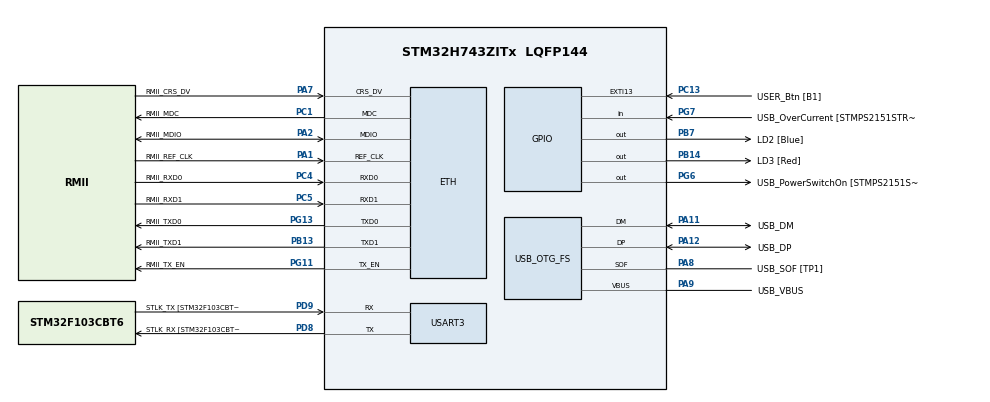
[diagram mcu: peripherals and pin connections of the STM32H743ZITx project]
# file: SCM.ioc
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CORTEX_M7.CPU_DCache=Enabled
CORTEX_M7.CPU_ICache=Disabled
ETH.MACAddr=00\:80\:E1\:00\:20\:10
ETH.MediaInterface=HAL_ETH_RMII_MODE
FREERTOS.Tasks01=defaultTask,0,128,StartDefaultTask,Default,NULL,Dynamic,NULL,NULL
FREERTOS.configENABLE_FPU=1
FREERTOS.configTOTAL_HEAP_SIZE=32768
FREERTOS.configUSE_NEWLIB_REENTRANT=1
Mcu.Family=STM32H7
Mcu.Name=STM32H743ZITx
Mcu.Package=LQFP144
NVIC.HASH_RNG_IRQn=true\:5\:0\:false\:false\:true\:true\:true\:true
NVIC.PriorityGroup=NVIC_PRIORITYGROUP_4
NVIC.TIM1_UP_IRQn=true\:15\:0\:false\:false\:true\:false\:false\:true
NVIC.TimeBase=TIM1_UP_IRQn
NVIC.TimeBaseIP=TIM1
PA1.GPIO_Label=RMII_REF_CLK
PA1.Mode=RMII
PA1.Signal=ETH_REF_CLK
PA10.GPIO_Label=USB_ID
PA10.Signal=USB_OTG_FS_ID
PA11.GPIO_Label=USB_DM
PA11.Mode=Device_Only
PA11.Signal=USB_OTG_FS_DM
PA12.GPIO_Label=USB_DP
PA12.Mode=Device_Only
PA12.Signal=USB_OTG_FS_DP
PA2.GPIO_Label=RMII_MDIO
PA2.Mode=RMII
PA2.Signal=ETH_MDIO
PA7.GPIO_Label=RMII_CRS_DV
PA7.Mode=RMII
PA7.Signal=ETH_CRS_DV
PA8.GPIO_Label=USB_SOF [TP1]
PA8.Mode=Activate_SOF_FS
PA8.Signal=USB_OTG_FS_SOF
PA9.GPIO_Label=USB_VBUS
PA9.Mode=Activate_VBUS
PA9.Signal=USB_OTG_FS_VBUS
PB13.GPIO_Label=RMII_TXD1
PB13.Mode=RMII
PB13.Signal=ETH_TXD1
PB14.GPIO_Label=LD3 [Red]
PB14.Signal=GPIO_Output
PB7.GPIO_Label=LD2 [Blue]
PB7.Signal=GPIO_Output
PC1.GPIO_Label=RMII_MDC
PC1.Mode=RMII
PC1.Signal=ETH_MDC
PC13.GPIO_Label=USER_Btn [B1]
PC13.Signal=GPXTI13
PC14-OSC32_IN\ (OSC32_IN).Mode=LSE-External-Oscillator
PC14-OSC32_IN\ (OSC32_IN).Signal=RCC_OSC32_IN
PC15-OSC32_OUT\ (OSC32_OUT).Mode=LSE-External-Oscillator
PC15-OSC32_OUT\ (OSC32_OUT).Signal=RCC_OSC32_OUT
PC4.GPIO_Label=RMII_RXD0
PC4.Mode=RMII
PC4.Signal=ETH_RXD0
PC5.GPIO_Label=RMII_RXD1
PC5.Mode=RMII
PC5.Signal=ETH_RXD1
PD8.GPIO_Label=STLK_RX [STM32F103CBT6_PA3]
PD8.Mode=Asynchronous
PD8.Signal=USART3_TX
PD9.GPIO_Label=STLK_TX [STM32F103CBT6_PA2]
PD9.Mode=Asynchronous
PD9.Signal=USART3_RX
PG11.GPIO_Label=RMII_TX_EN
PG11.Mode=RMII
PG11.Signal=ETH_TX_EN
PG13.GPIO_Label=RMII_TXD0
PG13.Mode=RMII
PG13.Signal=ETH_TXD0
PG6.GPIO_Label=USB_PowerSwitchOn [STMPS2151STR_EN]
PG6.Signal=GPIO_Output
PG7.GPIO_Label=USB_OverCurrent [STMPS2151STR_FAULT]
PG7.Signal=GPIO_Input
PH0-OSC_IN\ (PH0).GPIO_Label=MCO
PH0-OSC_IN\ (PH0).Mode=HSE-External-Clock-Source
PH0-OSC_IN\ (PH0).Signal=RCC_OSC_IN
PH1-OSC_OUT\ (PH1).Signal=RCC_OSC_OUT
ProjectManager.HeapSize=0x200
ProjectManager.StackSize=0x400
ProjectManager.TargetToolchain=STM32CubeIDE
RCC.48MHZClocksFreq_Value=24000000
RCC.ADCFreq_Value=16125000
RCC.AHBFreq_Value=216000000
RCC.APB1CLKDivider=RCC_HCLK_DIV4
RCC.APB1Freq_Value=60000000
RCC.APB1TimFreq_Value=108000000
RCC.APB2CLKDivider=RCC_HCLK_DIV2
RCC.APB2Freq_Value=120000000
RCC.APB2TimFreq_Value=216000000
RCC.APB3Freq_Value=120000000
RCC.APB4Freq_Value=120000000
RCC.CortexFreq_Value=240000000
RCC.D1PPRE=RCC_APB3_DIV2
RCC.D2PPRE1=RCC_APB1_DIV4
RCC.D2PPRE2=RCC_APB2_DIV2
RCC.D3PPRE=RCC_APB4_DIV2
RCC.DIVM1=1
RCC.DIVN1=60
RCC.DIVQ1=8
RCC.HCLKFreq_Value=240000000
RCC.HSE_VALUE=8000000
RCC.HSI_VALUE=64000000
RCC.PLLFRACN=0
RCC.PLLM=25
RCC.PLLMUL=RCC_PLL_MUL9
RCC.PLLN=432
RCC.PLLQ=9
RCC.PRESCALERUSB=RCC_USBCLKSOURCE_PLL_DIV1_5
RCC.PWR_Regulator_Voltage_Scale=PWR_REGULATOR_VOLTAGE_SCALE1
RCC.SYSCLKFreq_VALUE=240000000
RCC.SYSCLKSource=RCC_SYSCLKSOURCE_PLLCLK
RCC.SYSCLKSourceVirtual=RCC_SYSCLKSOURCE_PLLCLK
RCC.USBFreq_Value=60000000
RCC.VCOOutputFreq_Value=432000000
USART3.VirtualMode-Asynchronous=VM_ASYNC
USB_OTG_FS.VirtualMode=Device_Only
VP_FREERTOS_VS_CMSIS_V1.Mode=CMSIS_V1
VP_RNG_VS_RNG.Mode=RNG_Activate
VP_SYS_VS_tim1.Mode=TIM1
board=NUCLEO-H743ZI

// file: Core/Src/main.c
/* USER CODE BEGIN Header */
/**
  ******************************************************************************
  * @file           : main.c
  * @brief          : Main program body
  ******************************************************************************
  * @attention
  *
  * <h2><center>&copy; Copyright (c) 2021 STMicroelectronics.
  * All rights reserved.</center></h2>
  *
  * This software component is licensed by ST under BSD 3-Clause license,
  * the "License"; You may not use this file except in compliance with the
  * License. You may obtain a copy of the License at:
  *                        opensource.org/licenses/BSD-3-Clause
  *
  ******************************************************************************
  */
/* USER CODE END Header */
#include "main.h"
#include "string.h"
#include "cmsis_os.h"

/* USER CODE BEGIN Includes */
#include "freertos_functions.h"

/* USER CODE END Includes */

#if defined ( __ICCARM__ ) /*!< IAR Compiler */

#pragma location=0x30040000
ETH_DMADescTypeDef  DMARxDscrTab[ETH_RX_DESC_CNT]; /* Ethernet Rx DMA Descriptors */
#pragma location=0x30040060
ETH_DMADescTypeDef  DMATxDscrTab[ETH_TX_DESC_CNT]; /* Ethernet Tx DMA Descriptors */
#pragma location=0x30040200
uint8_t Rx_Buff[ETH_RX_DESC_CNT][ETH_MAX_PACKET_SIZE]; /* Ethernet Receive Buffers */

#elif defined ( __CC_ARM )  /* MDK ARM Compiler */

__attribute__((at(0x30040000))) ETH_DMADescTypeDef  DMARxDscrTab[ETH_RX_DESC_CNT]; /* Ethernet Rx DMA Descriptors */
__attribute__((at(0x30040060))) ETH_DMADescTypeDef  DMATxDscrTab[ETH_TX_DESC_CNT]; /* Ethernet Tx DMA Descriptors */
__attribute__((at(0x30040200))) uint8_t Rx_Buff[ETH_RX_DESC_CNT][ETH_MAX_PACKET_SIZE]; /* Ethernet Receive Buffer */

#elif defined ( __GNUC__ ) /* GNU Compiler */

ETH_DMADescTypeDef DMARxDscrTab[ETH_RX_DESC_CNT] __attribute__((section(".RxDecripSection"))); /* Ethernet Rx DMA Descriptors */
ETH_DMADescTypeDef DMATxDscrTab[ETH_TX_DESC_CNT] __attribute__((section(".TxDecripSection")));   /* Ethernet Tx DMA Descriptors */
uint8_t Rx_Buff[ETH_RX_DESC_CNT][ETH_MAX_PACKET_SIZE] __attribute__((section(".RxArraySection"))); /* Ethernet Receive Buffers */

#endif

ETH_TxPacketConfig TxConfig;

ETH_HandleTypeDef heth;

RNG_HandleTypeDef hrng;

UART_HandleTypeDef huart3;

PCD_HandleTypeDef hpcd_USB_OTG_FS;

osThreadId defaultTaskHandle;
/* USER CODE BEGIN PV */
osThreadId UnitiSideDataTaskHandle;
/* USER CODE END PV */

void SystemClock_Config(void);
static void MX_GPIO_Init(void);
static void MX_USART3_UART_Init(void);
static void MX_USB_OTG_FS_PCD_Init(void);
static void MX_RNG_Init(void);
static void MX_ETH_Init(void);
void StartDefaultTask(void const * argument);

int main(void)
{

  /* Enable D-Cache---------------------------------------------------------*/
  SCB_EnableDCache();

  /* MCU Configuration--------------------------------------------------------*/

  /* Reset of all peripherals, Initializes the Flash interface and the Systick. */
  HAL_Init();

  /* Configure the system clock */
  SystemClock_Config();

  /* Initialize all configured peripherals */
  MX_GPIO_Init();
  MX_USART3_UART_Init();
  MX_USB_OTG_FS_PCD_Init();
  MX_RNG_Init();
  MX_ETH_Init();

  /* Create the thread(s) */
  /* definition and creation of defaultTask */
  osThreadDef(defaultTask, StartDefaultTask, osPriorityNormal, 0, 128);
  defaultTaskHandle = osThreadCreate(osThread(defaultTask), NULL);

  /* USER CODE BEGIN RTOS_THREADS */
  /* add threads, ... */
  osThreadDef(unit_side_data_task, Unit_Side_Data_Task, osPriorityHigh, 0, 4096);
  UnitiSideDataTaskHandle = osThreadCreate(osThread(unit_side_data_task), NULL);

  osThreadDef(scm_side_data_task, SCM_Side_Data_Task, osPriorityHigh, 0, 4096);
  UnitiSideDataTaskHandle = osThreadCreate(osThread(scm_side_data_task), NULL);
  /* USER CODE END RTOS_THREADS */

  /* Start scheduler */
  osKernelStart();

  /* We should never get here as control is now taken by the scheduler */
  /* Infinite loop */
  while (1)
  {

  }
}

void SystemClock_Config(void)
{
  RCC_OscInitTypeDef RCC_OscInitStruct = {0};
  RCC_ClkInitTypeDef RCC_ClkInitStruct = {0};

  /** Supply configuration update enable
  */
  HAL_PWREx_ConfigSupply(PWR_LDO_SUPPLY);
  /** Configure the main internal regulator output voltage
  */
  __HAL_PWR_VOLTAGESCALING_CONFIG(PWR_REGULATOR_VOLTAGE_SCALE1);

  while(!__HAL_PWR_GET_FLAG(PWR_FLAG_VOSRDY)) {}
  /** Initializes the RCC Oscillators according to the specified parameters
  * in the RCC_OscInitTypeDef structure.
  */
  RCC_OscInitStruct.OscillatorType = RCC_OSCILLATORTYPE_HSI48|RCC_OSCILLATORTYPE_HSE;
  RCC_OscInitStruct.HSEState = RCC_HSE_BYPASS;
  RCC_OscInitStruct.HSI48State = RCC_HSI48_ON;
  RCC_OscInitStruct.PLL.PLLState = RCC_PLL_ON;
  RCC_OscInitStruct.PLL.PLLSource = RCC_PLLSOURCE_HSE;
  RCC_OscInitStruct.PLL.PLLM = 1;
  RCC_OscInitStruct.PLL.PLLN = 60;
  RCC_OscInitStruct.PLL.PLLP = 2;
  RCC_OscInitStruct.PLL.PLLQ = 8;
  RCC_OscInitStruct.PLL.PLLR = 2;
  RCC_OscInitStruct.PLL.PLLRGE = RCC_PLL1VCIRANGE_3;
  RCC_OscInitStruct.PLL.PLLVCOSEL = RCC_PLL1VCOWIDE;
  RCC_OscInitStruct.PLL.PLLFRACN = 0;
  if (HAL_RCC_OscConfig(&RCC_OscInitStruct) != HAL_OK)
  {
    Error_Handler();
  }
  /** Initializes the CPU, AHB and APB buses clocks
  */
  RCC_ClkInitStruct.ClockType = RCC_CLOCKTYPE_HCLK|RCC_CLOCKTYPE_SYSCLK
                              |RCC_CLOCKTYPE_PCLK1|RCC_CLOCKTYPE_PCLK2
                              |RCC_CLOCKTYPE_D3PCLK1|RCC_CLOCKTYPE_D1PCLK1;
  RCC_ClkInitStruct.SYSCLKSource = RCC_SYSCLKSOURCE_PLLCLK;
  RCC_ClkInitStruct.SYSCLKDivider = RCC_SYSCLK_DIV1;
  RCC_ClkInitStruct.AHBCLKDivider = RCC_HCLK_DIV1;
  RCC_ClkInitStruct.APB3CLKDivider = RCC_APB3_DIV2;
  RCC_ClkInitStruct.APB1CLKDivider = RCC_APB1_DIV4;
  RCC_ClkInitStruct.APB2CLKDivider = RCC_APB2_DIV2;
  RCC_ClkInitStruct.APB4CLKDivider = RCC_APB4_DIV2;

  if (HAL_RCC_ClockConfig(&RCC_ClkInitStruct, FLASH_LATENCY_0) != HAL_OK)
  {
    Error_Handler();
  }
}

static void MX_ETH_Init(void)
{

   static uint8_t MACAddr[6];

  heth.Instance = ETH;
  MACAddr[0] = 0x00;
  MACAddr[1] = 0x80;
  MACAddr[2] = 0xE1;
  MACAddr[3] = 0x00;
  MACAddr[4] = 0x20;
  MACAddr[5] = 0x10;
  heth.Init.MACAddr = &MACAddr[0];
  heth.Init.MediaInterface = HAL_ETH_RMII_MODE;
  heth.Init.TxDesc = DMATxDscrTab;
  heth.Init.RxDesc = DMARxDscrTab;
  heth.Init.RxBuffLen = 1524;

  if (HAL_ETH_Init(&heth) != HAL_OK)
  {
    Error_Handler();
  }

  memset(&TxConfig, 0 , sizeof(ETH_TxPacketConfig));
  TxConfig.Attributes = ETH_TX_PACKETS_FEATURES_CSUM | ETH_TX_PACKETS_FEATURES_CRCPAD;
  TxConfig.ChecksumCtrl = ETH_CHECKSUM_IPHDR_PAYLOAD_INSERT_PHDR_CALC;
  TxConfig.CRCPadCtrl = ETH_CRC_PAD_INSERT;

}

static void MX_RNG_Init(void)
{

  hrng.Instance = RNG;
  hrng.Init.ClockErrorDetection = RNG_CED_ENABLE;
  if (HAL_RNG_Init(&hrng) != HAL_OK)
  {
    Error_Handler();
  }

}

static void MX_USART3_UART_Init(void)
{

  huart3.Instance = USART3;
  huart3.Init.BaudRate = 115200;
  huart3.Init.WordLength = UART_WORDLENGTH_8B;
  huart3.Init.StopBits = UART_STOPBITS_1;
  huart3.Init.Parity = UART_PARITY_NONE;
  huart3.Init.Mode = UART_MODE_TX_RX;
  huart3.Init.HwFlowCtl = UART_HWCONTROL_NONE;
  huart3.Init.OverSampling = UART_OVERSAMPLING_16;
  huart3.Init.OneBitSampling = UART_ONE_BIT_SAMPLE_DISABLE;
  huart3.Init.ClockPrescaler = UART_PRESCALER_DIV1;
  huart3.AdvancedInit.AdvFeatureInit = UART_ADVFEATURE_NO_INIT;
  if (HAL_UART_Init(&huart3) != HAL_OK)
  {
    Error_Handler();
  }
  if (HAL_UARTEx_SetTxFifoThreshold(&huart3, UART_TXFIFO_THRESHOLD_1_8) != HAL_OK)
  {
    Error_Handler();
  }
  if (HAL_UARTEx_SetRxFifoThreshold(&huart3, UART_RXFIFO_THRESHOLD_1_8) != HAL_OK)
  {
    Error_Handler();
  }
  if (HAL_UARTEx_DisableFifoMode(&huart3) != HAL_OK)
  {
    Error_Handler();
  }

}

static void MX_USB_OTG_FS_PCD_Init(void)
{

  hpcd_USB_OTG_FS.Instance = USB_OTG_FS;
  hpcd_USB_OTG_FS.Init.dev_endpoints = 9;
  hpcd_USB_OTG_FS.Init.speed = PCD_SPEED_FULL;
  hpcd_USB_OTG_FS.Init.dma_enable = DISABLE;
  hpcd_USB_OTG_FS.Init.phy_itface = PCD_PHY_EMBEDDED;
  hpcd_USB_OTG_FS.Init.Sof_enable = ENABLE;
  hpcd_USB_OTG_FS.Init.low_power_enable = DISABLE;
  hpcd_USB_OTG_FS.Init.lpm_enable = DISABLE;
  hpcd_USB_OTG_FS.Init.battery_charging_enable = ENABLE;
  hpcd_USB_OTG_FS.Init.vbus_sensing_enable = ENABLE;
  hpcd_USB_OTG_FS.Init.use_dedicated_ep1 = DISABLE;
  if (HAL_PCD_Init(&hpcd_USB_OTG_FS) != HAL_OK)
  {
    Error_Handler();
  }

}

static void MX_GPIO_Init(void)
{
  GPIO_InitTypeDef GPIO_InitStruct = {0};

  /* GPIO Ports Clock Enable */
  __HAL_RCC_GPIOC_CLK_ENABLE();
  __HAL_RCC_GPIOH_CLK_ENABLE();
  __HAL_RCC_GPIOA_CLK_ENABLE();
  __HAL_RCC_GPIOB_CLK_ENABLE();
  __HAL_RCC_GPIOD_CLK_ENABLE();
  __HAL_RCC_GPIOG_CLK_ENABLE();

  /*Configure GPIO pin Output Level */
  HAL_GPIO_WritePin(GPIOB, LD3_Pin|LD2_Pin, GPIO_PIN_RESET);

  /*Configure GPIO pin Output Level */
  HAL_GPIO_WritePin(USB_PowerSwitchOn_GPIO_Port, USB_PowerSwitchOn_Pin, GPIO_PIN_RESET);

  /*Configure GPIO pin : USER_Btn_Pin */
  GPIO_InitStruct.Pin = USER_Btn_Pin;
  GPIO_InitStruct.Mode = GPIO_MODE_IT_RISING;
  GPIO_InitStruct.Pull = GPIO_NOPULL;
  HAL_GPIO_Init(USER_Btn_GPIO_Port, &GPIO_InitStruct);

  /*Configure GPIO pins : LD3_Pin LD2_Pin */
  GPIO_InitStruct.Pin = LD3_Pin|LD2_Pin;
  GPIO_InitStruct.Mode = GPIO_MODE_OUTPUT_PP;
  GPIO_InitStruct.Pull = GPIO_NOPULL;
  GPIO_InitStruct.Speed = GPIO_SPEED_FREQ_LOW;
  HAL_GPIO_Init(GPIOB, &GPIO_InitStruct);

  /*Configure GPIO pin : USB_PowerSwitchOn_Pin */
  GPIO_InitStruct.Pin = USB_PowerSwitchOn_Pin;
  GPIO_InitStruct.Mode = GPIO_MODE_OUTPUT_PP;
  GPIO_InitStruct.Pull = GPIO_NOPULL;
  GPIO_InitStruct.Speed = GPIO_SPEED_FREQ_LOW;
  HAL_GPIO_Init(USB_PowerSwitchOn_GPIO_Port, &GPIO_InitStruct);

  /*Configure GPIO pin : USB_OverCurrent_Pin */
  GPIO_InitStruct.Pin = USB_OverCurrent_Pin;
  GPIO_InitStruct.Mode = GPIO_MODE_INPUT;
  GPIO_InitStruct.Pull = GPIO_NOPULL;
  HAL_GPIO_Init(USB_OverCurrent_GPIO_Port, &GPIO_InitStruct);

}

void StartDefaultTask(void const * argument)
{
  for(;;)
  {
    osDelay(1);
  }
}

void HAL_TIM_PeriodElapsedCallback(TIM_HandleTypeDef *htim)
{
  if (htim->Instance == TIM1) {
    HAL_IncTick();
  }
}

void Error_Handler(void)
{
  __disable_irq();
  while (1)
  {
  }
}

/************************ (C) COPYRIGHT STMicroelectronics *****END OF FILE****/
